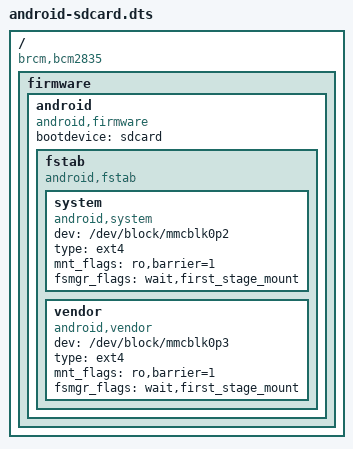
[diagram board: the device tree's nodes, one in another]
/dts-v1/;

/ {
	compatible = "brcm,bcm2835";

	fragment@0 {
		target-path = "/";

		__overlay__ {

			firmware {

				android {
					compatible = "android,firmware";
					bootdevice = "sdcard";

					fstab {
						compatible = "android,fstab";


						system {
							compatible = "android,system";
							dev = "/dev/block/mmcblk0p2";
							type = "ext4";
							mnt_flags = "ro,barrier=1";
							fsmgr_flags = "wait,first_stage_mount";
						};

						vendor {
							compatible = "android,vendor";
							dev = "/dev/block/mmcblk0p3";
							type = "ext4";
							mnt_flags = "ro,barrier=1";
							fsmgr_flags = "wait,first_stage_mount";
						};
					};
				};
			};
		};
	};
};
